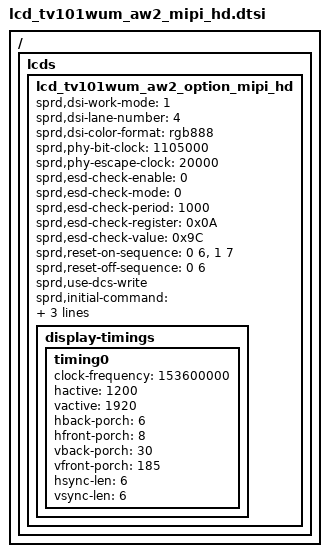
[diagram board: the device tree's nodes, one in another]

/*
 * tv105wum LCD config dtsi file for spreadtrum
 *
 * Copyright (C) 2018, Spreadtrum Communications Inc.
 * Copyright (C) 2023 Anhui Yunshu Zhihui Technology Co., Ltd.
 *
 * SPDX-License-Identifier: (GPL-2.0+ OR MIT)
 */

/ { lcds {
	lcd_tv101wum_aw2_option_mipi_hd: lcd_tv101wum_aw2_option_mipi_hd {

		sprd,dsi-work-mode = <1>; /* video burst mode*/
		sprd,dsi-lane-number = <4>;
		sprd,dsi-color-format = "rgb888";

		sprd,phy-bit-clock = <1105000>;	/* kbps */
		sprd,phy-escape-clock = <20000>;/* kHz */

		/*
		sprd,width-mm = <68>;
		sprd,height-mm = <121>;
		*/

		sprd,esd-check-enable = <0>;
		sprd,esd-check-mode = <0>;
		sprd,esd-check-period = <1000>;
		sprd,esd-check-register = <0x0A>;
		sprd,esd-check-value = <0x9C>;

		sprd,reset-on-sequence = <0 6>, <1 7>;
		sprd,reset-off-sequence = <0 6>;

		sprd,use-dcs-write;
		sprd,initial-command = [
			15 00 00 02 00 00
			39 00 00 04 FF 82 01 01
			15 00 00 02 00 80
			39 00 00 03 FF 82 01
			05 78 00 01 11
			05 64 00 01 29
			];

		sprd,sleep-in-command = [
            05 0A 00 01 28
            05 65 00 01 10
			];

/*		sprd,sleep-out-command = [
            13 64 00 01 11
            13 32 00 01 29
			]; */


		display-timings {
			timing0 {
				clock-frequency = <153600000>;
				hactive = <1200>;
				vactive = <1920>;
				hback-porch = <6>;
				hfront-porch = <8>;
				vback-porch = <30>;
				vfront-porch = <185>;
				hsync-len = <6>;
				vsync-len = <6>;
			};
		};
	};
};};
